# STM32MP13xx register map
File version: 1.5
CPU: CA7 r0p0, little endian, MPU, FPU, 4 interrupt priority bits
Registers are 32-bit, read-write, reset 0x0 unless marked. A register's access mark holds for its fields unless they carry their own. Offsets are from the block's base; [hi:lo] are bit positions; {n}, {i} and the like mark numbered series; 'fields as' and 'values as' point back to an identical list.

## RCC (part 5 of 7)
Base 0x50000000
0x730 RCC_MP_S_APB4ENSETR — This is a secure register for enabling the clock of the LTDC when it is used with a secure composition layer. A write access to this register field must be secure. A read access may be secure or non-secure. This register is used to set the peripheral clock enable bit of the corresponding peripheral. It shall be used to allocate a peripheral. Writing '0' has no effect, reading will return the effective values of the corresponding bits. Writing a '1' sets the corresponding bit to '1'.
  [0] LTDCEN — LTDC peripheral clocks enable Set by (secure) software.
    0=Writing '0' has no effect, reading '0' means that the peripheral clocks are disabled; 1=Writing '1' enables the peripheral clocks, reading '1' means that the peripheral clocks are enabled
0x734 RCC_MP_S_APB4ENCLRR — This is a secure register for enabling the clock of the LTDC when it is used with a secure composition layer.
  [0] LTDCEN — LTDC peripheral clocks enable Cleared by (secure) software.
    0=Writing '0' has no effect, reading '0' means that the peripheral clocks are disabled; 1=Writing '1' disables the peripheral clocks, reading '1' means that the peripheral clocks are enabled
0x738 RCC_MP_NS_APB4ENSETR — This is a non-secure register, for enabling the clock of the LTDC when it is used with one or two non-secure composition layers. This register is used to set the peripheral clock enable bit of the corresponding peripheral. It shall be used to allocate a peripheral. Writing '0' has no effect, reading will return the effective values of the corresponding bits. Writing a '1' sets the corresponding bit to '1'.
  [0] LTDCEN — LTDC peripheral clocks enable Set by software.
    values as RCC_MP_S_APB4ENSETR.LTDCEN
0x73C RCC_MP_NS_APB4ENCLRR — This is a non-secure register, for enabling the clock of the LTDC when it is used with one or two non-secure composition layers.
  [0] LTDCEN — LTDC peripheral clocks enable Cleared by software.
    values as RCC_MP_S_APB4ENCLRR.LTDCEN
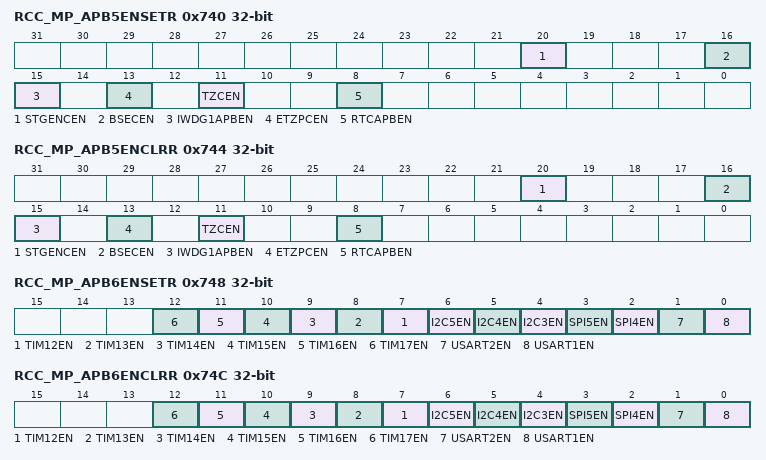
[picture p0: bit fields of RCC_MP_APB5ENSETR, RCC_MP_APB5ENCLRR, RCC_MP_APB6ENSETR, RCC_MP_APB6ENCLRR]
0x740 RCC_MP_APB5ENSETR — This register may be separately and securely write-protected at a field level, as detailed in the following register fields description. This register is used to set the peripheral clock enable bit of the corresponding peripheral. It shall be used to allocate a peripheral. Writing '0' has no effect, reading will return the effective values of the corresponding bits. Writing a '1' sets the corresponding bit to '1'.
  [20] STGENCEN — STGEN controller part, peripheral clocks enable If STGENC is configured as secure via the corresponding DECPROT[1] field of the ETZPC register, a write access to this register field must be secure. A read access may be secure or non-secure. Set by software. The peripheral clocks of the STGEN controller part are the pclk5, and the kernel clock as selected by the RCC_STGENCKSELR register.
    0=Writing '0' has no effect, reading '0' means that the pclk5 is disabled, and that the kernel clock gating is defined by RCC_MP_APB4ENxxxR.STGENROEN with xxx=SET/CLR; 1=Writing '1' enables the pclk5 and the kernel clock; reading '1' means that the pck5 and the kernel clock are enabled
  [16] BSECEN — BSEC peripheral clocks enable A write access to this register field must be secure. A read access may be secure or non-secure. Set by (secure) software.
    values as RCC_MP_S_APB4ENSETR.LTDCEN
  [15] IWDG1APBEN — IWDG1 APB clock enable If IWDG1 is configured as secure via the corresponding DECPROT[1] field of the ETZPC register, a write access to this register field must be secure. A read access may be secure or non-secure. Set by software.
    0=Writing '0' has no effect, reading '0' means that the APB clock is disabled; 1=Writing '1' enables the APB clock, reading '1' means that the APB clock is enabled
  [13] ETZPCEN — ETZPC peripheral clocks enable A write access to this register field must be secure. A read access may be secure or non-secure. Set by (secure) software.
    values as RCC_MP_S_APB4ENSETR.LTDCEN
  [11] TZCEN — TZC clocks enable Set by (secure) software. See for details.
    0=Writing '0' has no effect, reading '0' means that the peripheral clocks are disabled; 1=Writing '1' enables the pclk5 and aclk_tzc1 clocks, reading '1' means that the clocks are enabled
  [8] RTCAPBEN — RTC APB clock enable If at least one function of the RTC is configured as secure via the RTC_SECCFGR register (i.e. if the input signal rtc_sec driven by RTC is asserted), a write access to this register field must be secure. A read access may be secure or non-secure. Set by software.
    values as RCC_MP_S_APB4ENSETR.LTDCEN
0x744 RCC_MP_APB5ENCLRR — This register may be separately and securely write-protected at a field level, as detailed in the following register fields description. This register is used to clear the peripheral clock enable bit of the corresponding peripheral. It shall be used to deallocate a peripheral. Writing '0' has no effect, reading will return the effective values of the corresponding bits. Writing a '1' sets the corresponding bit to '0'.
  [20] STGENCEN — STGEN controller part, peripheral clocks enable If STGENC is configured as secure via the corresponding DECPROT[1] field of the ETZPC register, a write access to this register field must be secure. A read access may be secure or non-secure. Cleared by software. The peripheral clocks of the STGEN controller part are the pclk5, and the kernel clock as selected by the RCC_STGENCKSELR register.
    0=Writing '0' has no effect, reading '0' means that the pclk5 is disabled, and that the kernel clock gating is defined by RCC_MP_APB4ENxxxR.STGENROEN with xxx=SET/CLR; 1=Writing '1' enables the pclk5, and disables the kernel clock provided that RCC_MP_APB4ENSETR.STGENROEN=0 else it has no effect; reading '1' means that the pck5 and the kernel clock are enabled
  [16] BSECEN — BSEC peripheral clocks enable A write access to this register field must be secure. A read access may be secure or non-secure. Cleared by (secure) software.
    values as RCC_MP_S_APB4ENCLRR.LTDCEN
  [15] IWDG1APBEN — IWDG1 APB clock enable If IWDG1 is configured as secure via the corresponding DECPROT[1] field of the ETZPC register, a write access to this register field must be secure. A read access may be secure or non-secure. Cleared by software.
    0=Writing '0' has no effect, reading '0' means that the APB clock is disabled; 1=Writing '1' disables the APB clock, reading '1' means that the APB clock is enabled
  [13] ETZPCEN — ETZPC peripheral clocks enable A write access to this register field must be secure. A read access may be secure or non-secure. Cleared by (secure) software.
    values as RCC_MP_S_APB4ENCLRR.LTDCEN
  [11] TZCEN — TZC clocks enable Cleared by (secure) software. See for details.
    0=Writing '0' has no effect, reading '0' means that the peripheral clocks are disabled; 1=Writing '1' disables the pclk5 and aclk_tzc1 clocks, reading '1' means that the clocks are enabled
  [8] RTCAPBEN — RTC APB clock enable If at least one function of the RTC is configured as secure via the RTC_SECCFGR register (i.e. if the input signal rtc_sec driven by RTC is asserted), a write access to this register field must be secure. A read access may be secure or non-secure. Cleared by software.
    values as RCC_MP_S_APB4ENCLRR.LTDCEN
0x748 RCC_MP_APB6ENSETR — This register may be separately and securely write-protected at a field level depending on the secure state of the corresponding peripheral, i.e. depending on the corresponding DECPROT[1] field of the ETZPC register. This register is used to set the peripheral clock enable bit of the corresponding peripheral. It shall be used to allocate a peripheral. Writing '0' has no effect, reading will return the effective values of the corresponding bits. Writing a '1' sets the corresponding bit to '1'.
  [all] fields
    0=Writing '0' has no effect, reading '0' means that the peripherals clocks are disabled; 1=Writing '1' enables the peripherals clocks, reading '1' means that the peripherals clocks are enabled
  [n-5] TIM{n}EN (n=12..17) — TIM{n} peripherals clocks If TIM{n} is configured as secure via the corresponding DECPROT[1] field of the ETZPC register, a write access to this register field must be secure. A read access may be secure or non-secure. Set by software.
  [6] I2C5EN — I2C5 peripherals clocks If I2C5 is configured as secure via the corresponding DECPROT[1] field of the ETZPC register, a write access to this register field must be secure. A read access may be secure or non-secure. Set by software.
  [5] I2C4EN — I2C4 peripherals clocks If I2C4 is configured as secure via the corresponding DECPROT[1] field of the ETZPC register, a write access to this register field must be secure. A read access may be secure or non-secure. Set by software.
  [4] I2C3EN — I2C3 peripherals clocks If I2C3 is configured as secure via the corresponding DECPROT[1] field of the ETZPC register, a write access to this register field must be secure. A read access may be secure or non-secure. Set by software.
  [3] SPI5EN — SPI5 peripherals clocks If SPI5 is configured as secure via the corresponding DECPROT[1] field of the ETZPC register, a write access to this register field must be secure. A read access may be secure or non-secure. Set by software.
  [2] SPI4EN — SPI4 peripherals clocks If SPI4 is configured as secure via the corresponding DECPROT[1] field of the ETZPC register, a write access to this register field must be secure. A read access may be secure or non-secure. Set by software.
  [1] USART2EN — USART2 peripherals clocks If USART2 is configured as secure via the corresponding DECPROT[1] field of the ETZPC register, a write access to this register field must be secure. A read access may be secure or non-secure. Set by software.
  [0] USART1EN — USART1 peripherals clocks If USART1 is configured as secure via the corresponding DECPROT[1] field of the ETZPC register, a write access to this register field must be secure. A read access may be secure or non-secure. Set by software.
0x74C RCC_MP_APB6ENCLRR — This register may be separately and securely write-protected at a field level depending on the secure state of the corresponding peripheral, i.e. depending on the corresponding DECPROT[1] field of the ETZPC register. This register is used to clear the peripheral clock enable bit of the corresponding peripheral. It shall be used to deallocate a peripheral. Writing '0' has no effect, reading will return the effective values of the corresponding bits. Writing a '1' sets the corresponding bit to '0'.
  [all] fields
    0=Writing '0' has no effect, reading '0' means that the peripherals clocks are disabled; 1=Writing '1' disables the peripherals clocks, reading '1' means that the peripherals clocks are enabled
  [n-5] TIM{n}EN (n=12..17) — TIM{n} peripherals clocks If TIM{n} is configured as secure via the corresponding DECPROT[1] field of the ETZPC register, a write access to this register field must be secure. A read access may be secure or non-secure. Set by software.
  [6] I2C5EN — I2C5 peripherals clocks If I2C5 is configured as secure via the corresponding DECPROT[1] field of the ETZPC register, a write access to this register field must be secure. A read access may be secure or non-secure. Set by software.
  [5] I2C4EN — I2C4 peripherals clocks If I2C4 is configured as secure via the corresponding DECPROT[1] field of the ETZPC register, a write access to this register field must be secure. A read access may be secure or non-secure. Set by software.
  [4] I2C3EN — I2C3 peripherals clocks If I2C3 is configured as secure via the corresponding DECPROT[1] field of the ETZPC register, a write access to this register field must be secure. A read access may be secure or non-secure. Set by software.
  [3] SPI5EN — SPI5 peripherals clocks If SPI5 is configured as secure via the corresponding DECPROT[1] field of the ETZPC register, a write access to this register field must be secure. A read access may be secure or non-secure. Set by software.
  [2] SPI4EN — SPI4 peripherals clocks If SPI4 is configured as secure via the corresponding DECPROT[1] field of the ETZPC register, a write access to this register field must be secure. A read access may be secure or non-secure. Set by software.
  [1] USART2EN — USART2 peripherals clocks If USART2 is configured as secure via the corresponding DECPROT[1] field of the ETZPC register, a write access to this register field must be secure. A read access may be secure or non-secure. Set by software.
  [0] USART1EN — USART1 peripherals clocks If USART1 is configured as secure via the corresponding DECPROT[1] field of the ETZPC register, a write access to this register field must be secure. A read access may be secure or non-secure. Set by software.
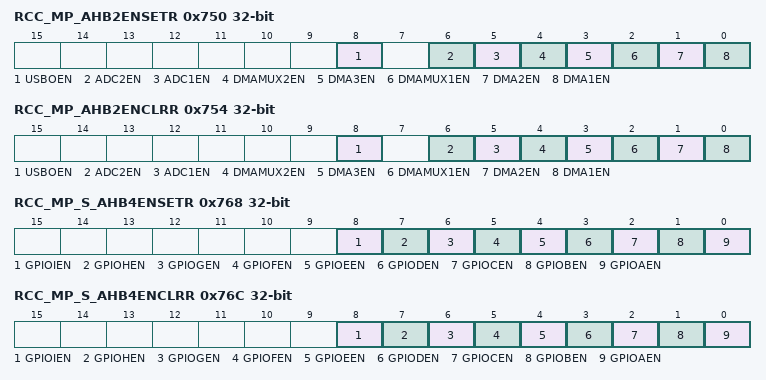
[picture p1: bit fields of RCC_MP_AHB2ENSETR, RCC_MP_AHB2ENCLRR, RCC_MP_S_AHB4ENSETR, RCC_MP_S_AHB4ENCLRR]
0x750 RCC_MP_AHB2ENSETR — This register may be separately and securely write-protected at a field level depending on the secure state of the corresponding peripheral, i.e. depending on the corresponding DECPROT[1] field of the ETZPC register. This register is used to set the peripheral clock enable bit of the corresponding peripheral. It shall be used to allocate a peripheral. Writing '0' has no effect, reading will return the effective values of the corresponding bits. Writing a '1' sets the corresponding bit to '1'.
  [all] fields
    values as RCC_MP_S_APB4ENSETR.LTDCEN
  [8] USBOEN — USBO peripheral clocks enable If USBO is configured as secure via the corresponding DECPROT[1] field of the ETZPC register, a write access to this register field must be secure. A read access may be secure or non-secure. Set by software.
  [6] ADC2EN — ADC2 peripheral clocks enable If ADC2 is configured as secure via the corresponding DECPROT[1] field of the ETZPC register, a write access to this register field must be secure. A read access may be secure or non-secure. Set by software.
  [5] ADC1EN — ADC1 peripheral clocks enable If ADC1 is configured as secure via the corresponding DECPROT[1] field of the ETZPC register, a write access to this register field must be secure. A read access may be secure or non-secure. Set by software.
  [4] DMAMUX2EN — DMAMUX2 peripheral clocks enable If DMAMUX2 is configured as secure via the corresponding DECPROT[1] field of the ETZPC register, a write access to this register field must be secure. A read access may be secure or non-secure. Set by software.
  [3] DMA3EN — DMA3 peripheral clocks enable If DMA3 is configured as secure via the corresponding DECPROT[1] field of the ETZPC register, a write access to this register field must be secure. A read access may be secure or non-secure. Set by software.
  [2] DMAMUX1EN — DMAMUX1 peripheral clocks enable Set by software.
  [1] DMA2EN — DMA2 peripheral clocks enable Set by software.
  [0] DMA1EN — DMA1 peripheral clocks enable Set by software.
0x754 RCC_MP_AHB2ENCLRR — This register may be separately and securely write-protected at a field level depending on the secure state of the corresponding peripheral, i.e. depending on the corresponding DECPROT[1] field of the ETZPC register. This register is used to clear the peripheral clock enable bit of the corresponding peripheral. It shall be used to deallocate a peripheral. Writing '0' has no effect, reading will return the effective values of the corresponding bits. Writing a '1' sets the corresponding bit to '0'.
  [all] fields
    values as RCC_MP_S_APB4ENCLRR.LTDCEN
  [8] USBOEN — USBO peripheral clocks enable If USBO is configured as secure via the corresponding DECPROT[1] field of the ETZPC register, a write access to this register field must be secure. A read access may be secure or non-secure. Cleared by software.
  [6] ADC2EN — ADC2 peripheral clocks enable If ADC2 is configured as secure via the corresponding DECPROT[1] field of the ETZPC register, a write access to this register field must be secure. A read access may be secure or non-secure. Cleared by software.
  [5] ADC1EN — ADC1 peripheral clocks enable If ADC1 is configured as secure via the corresponding DECPROT[1] field of the ETZPC register, a write access to this register field must be secure. A read access may be secure or non-secure. Cleared by software.
  [4] DMAMUX2EN — DMAMUX2 peripheral clocks enable If DMAMUX2 is configured as secure via the corresponding DECPROT[1] field of the ETZPC register, a write access to this register field must be secure. A read access may be secure or non-secure. Cleared by software.
  [3] DMA3EN — DMA3 peripheral clocks enable If DMA3 is configured as secure via the corresponding DECPROT[1] field of the ETZPC register, a write access to this register field must be secure. A read access may be secure or non-secure. Cleared by software.
  [2] DMAMUX1EN — DMAMUX1 peripheral clocks enable Cleared by software.
  [1] DMA2EN — DMA2 peripheral clocks enable Cleared by software.
  [0] DMA1EN — DMA1 peripheral clocks enable Cleared by software.
0x760 RCC_MP_AHB4ENSETR — This register may be write-protected depending on the secure state of the TSC peripheral, i.e. depending on the corresponding DECPROT[1] field of the ETZPC register. This register is used to set the peripheral clock enable bit of the corresponding peripheral. It shall be used to allocate a peripheral. Writing '0' has no effect, reading will return the effective values of the corresponding bits. Writing a '1' sets the corresponding bit to '0'.
  [15] TSCEN — TSC peripheral clocks enable Set by software.
    values as RCC_MP_S_APB4ENSETR.LTDCEN
0x764 RCC_MP_AHB4ENCLRR — This register may be write-protected depending on the secure state of the TSC peripheral, i.e. depending on the corresponding DECPROT[1] field of the ETZPC register. This register is used to clear the peripheral clock enable bit of the corresponding peripheral. It shall be used to deallocate a peripheral. Writing '0' has no effect, reading will return the effective values of the corresponding bits. Writing a '1' sets the corresponding bit to '0'.
  [15] TSCEN — TSC peripheral clocks enable Cleared by software.
    values as RCC_MP_S_APB4ENCLRR.LTDCEN
0x768 RCC_MP_S_AHB4ENSETR — This is a secure register, for enabling the clock of the secure (AHB4) GPIO ports, as defined by the GPIO register file and more specifically the GPIOxSECCFGR.SECy control bit with x=A..I, and y = 0..15 (or 2 for x=I). A write access to this register field must be secure. A read access may be secure or non-secure. This register is used to set the peripheral clock enable bit of the corresponding peripheral. It shall be used to allocate a peripheral. Writing '0' has no effect, reading will return the effective values of the corresponding bits. Writing a '1' sets the corresponding bit to '1'.
  [all] fields
    values as RCC_MP_S_APB4ENSETR.LTDCEN
  [8] GPIOIEN — GPIOI peripheral clocks enable Set by (secure) software.
  [7] GPIOHEN — GPIOH peripheral clocks enable Set by (secure) software.
  [6] GPIOGEN — GPIOG peripheral clocks enable Set by (secure) software.
  [5] GPIOFEN — GPIOF peripheral clocks enable Set by (secure) software.
  [4] GPIOEEN — GPIOE peripheral clocks enable Set by (secure) software.
  [3] GPIODEN — GPIOD peripheral clocks enable Set by (secure) software.
  [2] GPIOCEN — GPIOC peripheral clocks enable Set by (secure) software.
  [1] GPIOBEN — GPIOB peripheral clocks enable Set by (secure) software.
  [0] GPIOAEN — GPIOA peripheral clocks enable Set by (secure) software.
0x76C RCC_MP_S_AHB4ENCLRR — This is a secure register, for disabling of the secure (AHB4) GPIO ports, as defined by the GPIO register file and more specifically the GPIOxSECCFGR.SECy control bit with x=A..I, and y = 0..15 (or 2 for x=I). A write access to this register field must be secure. A read access may be secure or non-secure. This register is used to clear the peripheral clock enable bit of the corresponding peripheral. It shall be used to deallocate a peripheral. Writing '0' has no effect, reading will return the effective values of the corresponding bits. Writing a '1' sets the corresponding bit to '0'.
  [all] fields
    values as RCC_MP_S_APB4ENSETR.LTDCEN
  [8] GPIOIEN — GPIOI peripheral clocks enable Cleared by (secure) software.
  [7] GPIOHEN — GPIOH peripheral clocks enable Cleared by (secure) software.
  [6] GPIOGEN — GPIOG peripheral clocks enable Cleared by (secure) software.
  [5] GPIOFEN — GPIOF peripheral clocks enable Cleared by (secure) software.
  [4] GPIOEEN — GPIOE peripheral clocks enable Cleared by (secure) software.
  [3] GPIODEN — GPIOD peripheral clocks enable Cleared by (secure) software.
  [2] GPIOCEN — GPIOC peripheral clocks enable Cleared by (secure) software.
  [1] GPIOBEN — GPIOB peripheral clocks enable Cleared by (secure) software.
  [0] GPIOAEN — GPIOA peripheral clocks enable Cleared by (secure) software.
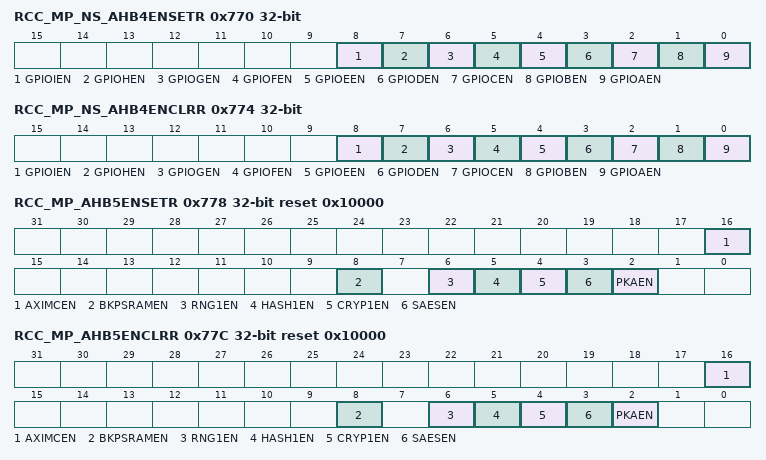
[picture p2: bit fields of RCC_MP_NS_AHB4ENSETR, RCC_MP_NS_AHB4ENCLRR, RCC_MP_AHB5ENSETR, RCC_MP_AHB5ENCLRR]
0x770 RCC_MP_NS_AHB4ENSETR — This is a non-secure register, for enabling the non-secure GPIO ports, as defined by the GPIO register file and more specifically the GPIOxSECCFGR.SECy control bit with x=A..I, and y = 0..15 (or 2 for x=I). This register is used to set the peripheral clock enable bit of the corresponding peripheral. It shall be used to allocate a peripheral. Writing '0' has no effect, reading will return the effective values of the corresponding bits. Writing a '1' sets the corresponding bit to '1'.
  [all] fields
    values as RCC_MP_S_APB4ENSETR.LTDCEN
  [8] GPIOIEN — GPIOI peripheral clocks enable Set by software.
  [7] GPIOHEN — GPIOH peripheral clocks enable Set by software.
  [6] GPIOGEN — GPIOG peripheral clocks enable Set by software.
  [5] GPIOFEN — GPIOF peripheral clocks enable Set by software.
  [4] GPIOEEN — GPIOE peripheral clocks enable Set by software.
  [3] GPIODEN — GPIOD peripheral clocks enable Set by software.
  [2] GPIOCEN — GPIOC peripheral clocks enable Set by software.
  [1] GPIOBEN — GPIOB peripheral clocks enable Set by software.
  [0] GPIOAEN — GPIOA peripheral clocks enable Set by software.
0x774 RCC_MP_NS_AHB4ENCLRR — This is a non-secure register, for disabling the non-secure GPIO ports, as defined by the GPIO register file and more specifically the GPIOxSECCFGR.SECy control bit with x=A..I, and y = 0..15 (or 2 for x=I). This register is used to clear the peripheral clock enable bit of the corresponding peripheral. It shall be used to deallocate a peripheral. Writing '0' has no effect, reading will return the effective values of the corresponding bits. Writing a '1' sets the corresponding bit to '0'.
  [all] fields
    values as RCC_MP_S_APB4ENCLRR.LTDCEN
  [8] GPIOIEN — GPIOI peripheral clocks enable Cleared by software.
  [7] GPIOHEN — GPIOH peripheral clocks enable Cleared by software.
  [6] GPIOGEN — GPIOG peripheral clocks enable Cleared by software.
  [5] GPIOFEN — GPIOF peripheral clocks enable Cleared by software.
  [4] GPIOEEN — GPIOE peripheral clocks enable Cleared by software.
  [3] GPIODEN — GPIOD peripheral clocks enable Cleared by software.
  [2] GPIOCEN — GPIOC peripheral clocks enable Cleared by software.
  [1] GPIOBEN — GPIOB peripheral clocks enable Cleared by software.
  [0] GPIOAEN — GPIOA peripheral clocks enable Cleared by software.
0x778 RCC_MP_AHB5ENSETR reset 0x10000 — This register may be separately and securely write-protected at a field level, as detailed in the following register fields description. This register is used to set the peripheral clock enable bit of the corresponding peripheral. It shall be used to allocate a peripheral to the MPU. Writing '0' has no effect, reading will return the effective values of the corresponding bits. Writing a '1' sets the corresponding bit to '1'.
  [all] fields
    values as RCC_MP_S_APB4ENSETR.LTDCEN
  [16] AXIMCEN — AXIMC clocks enable A write access to this register field must be secure. A read access may be secure or non-secure. Set by (secure) software.
  [8] BKPSRAMEN — BKPSRAM clocks enable If BKPSRAM is configured as secure via the corresponding DECPROT[1] field of the ETZPC register, a write access to this register field must be secure. A read access may be secure or non-secure. Set by software.
  [6] RNG1EN — RNG1 peripheral clocks enable If RNG1 is configured as secure via the corresponding DECPROT[1] field of the ETZPC register, a write access to this register field must be secure. A read access may be secure or non-secure. Set by software.
  [5] HASH1EN — HASH peripheral clocks enable If HASH is configured as secure via the corresponding DECPROT[1] field of the ETZPC register, a write access to this register field must be secure. A read access may be secure or non-secure. Set by software.
  [4] CRYP1EN — CRYP (3DES/AES) peripheral clocks enable If CRYP is configured as secure via the corresponding DECPROT[1] field of the ETZPC register, a write access to this register field must be secure. A read access may be secure or non-secure. Set by software.
  [3] SAESEN — SAES peripheral clocks enable If SAES is configured as secure via the corresponding DECPROT[1] field of the ETZPC register, a write access to this register field must be secure. A read access may be secure or non-secure. Set by software.
  [2] PKAEN — PKA peripheral clocks enable If PKA is configured as secure via the corresponding DECPROT[1] field of the ETZPC register, a write access to this register field must be secure. A read access may be secure or non-secure. Set by software.
0x77C RCC_MP_AHB5ENCLRR reset 0x10000 — This register may be separately and securely write-protected at a field level, as detailed in the following register fields description. This register is used to clear the peripheral clock enable bit of the corresponding peripheral. It shall be used to deallocate a peripheral. Writing '0' has no effect, reading will return the effective values of the corresponding bits. Writing a '1' sets the corresponding bit to '0'.
  [all] fields
    values as RCC_MP_S_APB4ENCLRR.LTDCEN
  [16] AXIMCEN — AXIMC clocks enable A write access to this register field must be secure. A read access may be secure or non-secure. Cleared by (secure) software.
  [8] BKPSRAMEN — BKPSRAM clocks enable If BKPSRAM is configured as secure via the corresponding DECPROT[1] field of the ETZPC register, a write access to this register field must be secure. A read access may be secure or non-secure. Cleared by software.
  [6] RNG1EN — RNG1 peripheral clocks enable If RNG1 is configured as secure via the corresponding DECPROT[1] field of the ETZPC register, a write access to this register field must be secure. A read access may be secure or non-secure. Cleared by software.
  [5] HASH1EN — HASH peripheral clocks enable If HASH is configured as secure via the corresponding DECPROT[1] field of the ETZPC register, a write access to this register field must be secure. A read access may be secure or non-secure. Cleared by software.
  [4] CRYP1EN — CRYP (3DES/AES) peripheral clocks enable If CRYP is configured as secure via the corresponding DECPROT[1] field of the ETZPC register, a write access to this register field must be secure. A read access may be secure or non-secure. Cleared by software.
  [3] SAESEN — SAES peripheral clocks enable If SAES is configured as secure via the corresponding DECPROT[1] field of the ETZPC register, a write access to this register field must be secure. A read access may be secure or non-secure. Cleared by software.
  [2] PKAEN — PKA peripheral clocks enable If PKA is configured as secure via the corresponding DECPROT[1] field of the ETZPC register, a write access to this register field must be secure. A read access may be secure or non-secure. Cleared by software.
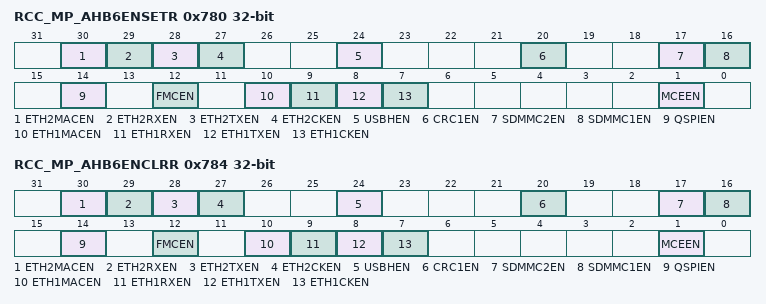
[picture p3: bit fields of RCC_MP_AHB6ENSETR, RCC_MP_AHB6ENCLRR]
0x780 RCC_MP_AHB6ENSETR — This register may be separately and securely write-protected at a field level, as detailed in the following register fields description. This register is used to set the peripheral clock enable bit of the corresponding peripheral. It shall be used to allocate a peripheral. Writing '0' has no effect, reading will return the effective values of the corresponding bits. Writing a '1' sets the corresponding bit to '1'.
  [30] ETH2MACEN — ETH2 MAC bus interface clock enable (hclk6 and aclk) If ETH2 is configured as secure via the corresponding DECPROT[1] field of the ETZPC register, a write access to this register field must be secure. A read access may be secure or non-secure. Set by software.
    0=Writing '0' has no effect, reading '0' means that the bus interface clock is disabled; 1=Writing '1' enables the bus interface clock, reading '1' means that the bus interface clock is enabled
  [29] ETH2RXEN — ETH2 reception clock enable If ETH2 is configured as secure via the corresponding DECPROT[1] field of the ETZPC register, a write access to this register field must be secure. A read access may be secure or non-secure. Set by software.
    0=Writing '0' has no effect, reading '0' means that the reception clock is disabled; 1=Writing '1' enables the reception clock, reading '1' means that the reception clock is enabled
  [28] ETH2TXEN — ETH2 transmission clock enable If ETH2 is configured as secure via the corresponding DECPROT[1] field of the ETZPC register, a write access to this register field must be secure. A read access may be secure or non-secure. Set by software.
    0=Writing '0' has no effect, reading '0' means that the transmission clock is disabled; 1=Writing '1' enables the transmission clock, reading '1' means that the transmission clock is enabled
  [27] ETH2CKEN — Enable of the ETH2 clock generated by the RCC (eth2_ker_ck) If ETH2 is configured as secure via the corresponding DECPROT[1] field of the ETZPC register, a write access to this register field must be secure. A read access may be secure or non-secure. Set by software.
    0=Writing '0' has no effect, reading '0' means that eth2_ker_ck clock is disabled; 1=Writing '1' enables the eth2_ker_ck clock, reading '1' means that the eth2_ker_ck clock is enabled
  [24] USBHEN — USBH peripheral clocks enable Set by software.
    values as RCC_MP_S_APB4ENSETR.LTDCEN
  [20] CRC1EN — CRC peripheral clocks enable Set by software.
    values as RCC_MP_S_APB4ENSETR.LTDCEN
  [17] SDMMC2EN — SDMMC2 and SDMMC2 delay (DLYBSD2) block peripheral clocks enable If SDMMC2 is configured as secure via the corresponding DECPROT[1] field of the ETZPC register, a write access to this register field must be secure. A read access may be secure or non-secure. Set by software.
    values as RCC_MP_S_APB4ENSETR.LTDCEN
  [16] SDMMC1EN — SDMMC1 and SDMMC1 delay (DLYBSD1) block peripheral clocks enable If SDMMC1 is configured as secure via the corresponding DECPROT[1] field of the ETZPC register, a write access to this register field must be secure. A read access may be secure or non-secure. Set by software.
    values as RCC_MP_S_APB4ENSETR.LTDCEN
  [14] QSPIEN — QUADSPI peripheral clocks enable If QSPI is configured as secure via the corresponding DECPROT[1] field of the ETZPC register, a write access to this register field must be secure. A read access may be secure or non-secure. Set by software.
    values as RCC_MP_S_APB4ENSETR.LTDCEN
  [12] FMCEN — FMC peripheral clocks enable If FMC is configured as secure via the corresponding DECPROT[1] field of the ETZPC register, a write access to this register field must be secure. A read access may be secure or non-secure. Set by software.
    values as RCC_MP_S_APB4ENSETR.LTDCEN
  [10] ETH1MACEN — ETH1 MAC bus interface clock enable (hclk6 and aclk) If ETH1 is configured as secure via the corresponding DECPROT[1] field of the ETZPC register, a write access to this register field must be secure. A read access may be secure or non-secure. Set by software.
    values as ETH2MACEN
  [9] ETH1RXEN — ETH1 reception clock enable If ETH1 is configured as secure via the corresponding DECPROT[1] field of the ETZPC register, a write access to this register field must be secure. A read access may be secure or non-secure. Set by software.
    values as ETH2RXEN
  [8] ETH1TXEN — ETH1 transmission clock enable If ETH1 is configured as secure via the corresponding DECPROT[1] field of the ETZPC register, a write access to this register field must be secure. A read access may be secure or non-secure. Set by software.
    values as ETH2TXEN
  [7] ETH1CKEN — Enable of the ETH1 clock generated by the RCC (eth1_ker_ck) If ETH1 is configured as secure via the corresponding DECPROT[1] field of the ETZPC register, a write access to this register field must be secure. A read access may be secure or non-secure. Set by software.
    0=Writing '0' has no effect, reading '0' means that eth1_ker_ck clock is disabled; 1=Writing '1' enables the eth1_ker_ck clock, reading '1' means that the eth1_ker_ck clock is enabled
  [1] MCEEN — MCE peripheral clocks enable If MCE is configured as secure via the corresponding DECPROT[1] field of the ETZPC register, a write access to this register field must be secure. A read access may be secure or non-secure. Set by software.
    values as RCC_MP_S_APB4ENSETR.LTDCEN
0x784 RCC_MP_AHB6ENCLRR — This register may be separately and securely write-protected at a field level, as detailed in the following register fields description. This register is used to clear the peripheral clock enable bit of the corresponding peripheral. It shall be used to deallocate a peripheral. Writing '0' has no effect, reading will return the effective values of the corresponding bits. Writing a '1' sets the corresponding bit to '0'.
  [30] ETH2MACEN — ETH2 MAC bus interface clock enable (hclk6 and aclk) If ETH2 is configured as secure via the corresponding DECPROT[1] field of the ETZPC register, a write access to this register field must be secure. A read access may be secure or non-secure. Cleared by software.
    0=Writing '0' has no effect, reading '0' means that the bus interface clock is disabled; 1=Writing '1' disables the bus interface clock, reading '1' means that the bus interface clock is enabled
  [29] ETH2RXEN — ETH2 reception clock enable If ETH2 is configured as secure via the corresponding DECPROT[1] field of the ETZPC register, a write access to this register field must be secure. A read access may be secure or non-secure. Cleared by software.
    0=Writing '0' has no effect, reading '0' means that the reception clock is disabled; 1=Writing '1' disables the reception clock, reading '1' means that the reception clock is enabled
  [28] ETH2TXEN — ETH2 transmission clock enable If ETH2 is configured as secure via the corresponding DECPROT[1] field of the ETZPC register, a write access to this register field must be secure. A read access may be secure or non-secure. Cleared by software.
    0=Writing '0' has no effect, reading '0' means that the transmission clock is disabled; 1=Writing '1' disables the transmission clock, reading '1' means that the transmission clock is enabled
  [27] ETH2CKEN — Enable of the ETH2 clock generated by the RCC (eth2_ker_ck) If ETH2 is configured as secure via the corresponding DECPROT[1] field of the ETZPC register, a write access to this register field must be secure. A read access may be secure or non-secure. Cleared by software.
    0=Writing '0' has no effect, reading '0' means that eth2_ker_ck clock is disabled; 1=Writing '1' disables the eth2_ker_ck clock, reading '1' means that the eth2_ker_ck clock is enabled
  [24] USBHEN — USBH peripheral clocks enable Cleared by software.
    values as RCC_MP_S_APB4ENCLRR.LTDCEN
  [20] CRC1EN — CRC peripheral clocks enable Cleared by software.
    values as RCC_MP_S_APB4ENCLRR.LTDCEN
  [17] SDMMC2EN — SDMMC2 and SDMMC2 delay (DLYBSD2) block peripheral clocks enable If SDMMC2 is configured as secure via the corresponding DECPROT[1] field of the ETZPC register, a write access to this register field must be secure. A read access may be secure or non-secure. Cleared by software.
    values as RCC_MP_S_APB4ENCLRR.LTDCEN
  [16] SDMMC1EN — SDMMC1 and SDMMC1 delay (DLYBSD1) block peripheral clocks enable If SDMMC1 is configured as secure via the corresponding DECPROT[1] field of the ETZPC register, a write access to this register field must be secure. A read access may be secure or non-secure. Cleared by software.
    values as RCC_MP_S_APB4ENCLRR.LTDCEN
  [14] QSPIEN — QUADSPI peripheral clocks enable If QSPI is configured as secure via the corresponding DECPROT[1] field of the ETZPC register, a write access to this register field must be secure. A read access may be secure or non-secure. Cleared by software.
    values as RCC_MP_S_APB4ENCLRR.LTDCEN
  [12] FMCEN — FMC peripheral clocks enable If FMC is configured as secure via the corresponding DECPROT[1] field of the ETZPC register, a write access to this register field must be secure. A read access may be secure or non-secure. Cleared by software.
    values as RCC_MP_S_APB4ENCLRR.LTDCEN
  [10] ETH1MACEN — ETH1 MAC bus interface clock enable (hclk6 and aclk) If ETH1 is configured as secure via the corresponding DECPROT[1] field of the ETZPC register, a write access to this register field must be secure. A read access may be secure or non-secure. Cleared by software.
    values as ETH2MACEN
  [9] ETH1RXEN — ETH1 reception clock enable If ETH1 is configured as secure via the corresponding DECPROT[1] field of the ETZPC register, a write access to this register field must be secure. A read access may be secure or non-secure. Cleared by software.
    values as ETH2RXEN
  [8] ETH1TXEN — ETH1 transmission clock enable If ETH1 is configured as secure via the corresponding DECPROT[1] field of the ETZPC register, a write access to this register field must be secure. A read access may be secure or non-secure. Cleared by software.
    values as ETH2TXEN
  [7] ETH1CKEN — Enable of the ETH1 clock generated by the RCC (eth1_ker_ck) If ETH1 is configured as secure via the corresponding DECPROT[1] field of the ETZPC register, a write access to this register field must be secure. A read access may be secure or non-secure. Cleared by software.
    0=Writing '0' has no effect, reading '0' means that eth1_ker_ck clock is disabled; 1=Writing '1' disables the eth1_ker_ck clock, reading '1' means that the eth1_ker_ck clock is enabled
  [1] MCEEN — MCE peripheral clocks enable If MCE is configured as secure via the corresponding DECPROT[1] field of the ETZPC register, a write access to this register field must be secure. A read access may be secure or non-secure. Cleared by software.
    values as RCC_MP_S_APB4ENCLRR.LTDCEN
0x788 RCC_MP_S_AHB6ENSETR — This is a secure register for enabling the clock of the MDMA when it is used as secure. A write access to this register field must be secure. A read access may be secure or non- secure. This register is used to set the peripheral clock enable bit of the corresponding peripheral. It shall be used to allocate a peripheral. Writing '0' has no effect, reading will return the effective values of the corresponding bits. Writing a '1' sets the corresponding bit to '1'.
  [0] MDMAEN — MDMA peripheral clocks enable Set by (secure) software.
    values as RCC_MP_S_APB4ENSETR.LTDCEN
0x78C RCC_MP_S_AHB6ENCLRR — This is a secure register for disabling the clock of the MDMA when it is not used as secure. A write access to this register field must be secure. A read access may be secure or non- secure. This register is used to clear the peripheral clock enable bit of the corresponding peripheral. It shall be used to deallocate a peripheral. Writing '0' has no effect, reading will return the effective values of the corresponding bits. Writing a '1' sets the corresponding bit to '0'.
  [0] MDMAEN — MDMA peripheral clocks enable Cleared by (secure) software.
    values as RCC_MP_S_APB4ENCLRR.LTDCEN
